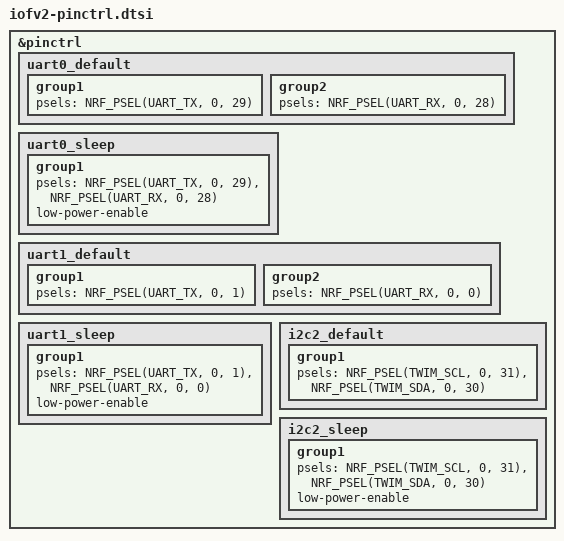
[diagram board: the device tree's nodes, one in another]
&pinctrl {


	uart0_default: uart0_default {
		group1 {
			psels = <NRF_PSEL(UART_TX, 0, 29)>;
		};
        group2 {
            psels = <NRF_PSEL(UART_RX, 0, 28)>;
        };

	};
	/* required if CONFIG_PM_DEVICE=y */
	uart0_sleep: uart0_sleep {
		group1 {
			psels = <NRF_PSEL(UART_TX, 0, 29)>,
					<NRF_PSEL(UART_RX, 0, 28)>;
			low-power-enable;
		};
	};

	uart1_default: uart1_default {
		group1 {
			psels = <NRF_PSEL(UART_TX, 0, 1)>;
		};
        group2 {
            psels = <NRF_PSEL(UART_RX, 0, 0)>;
        };
	};

	uart1_sleep: uart1_sleep {
		group1 {
			psels = <NRF_PSEL(UART_TX, 0, 1)>,
					<NRF_PSEL(UART_RX, 0, 0)>;
			low-power-enable;
		};
	};

	i2c2_default: i2c2_default {
		group1 {
			psels = <NRF_PSEL(TWIM_SCL, 0, 31)>, <NRF_PSEL(TWIM_SDA, 0, 30)>;
		};
	};

	i2c2_sleep: i2c2_sleep {
		group1 {
			psels = <NRF_PSEL(TWIM_SCL, 0, 31)>, 
					<NRF_PSEL(TWIM_SDA, 0, 30)>;
			low-power-enable;
		};
	};
};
